# STM32U5G9 register map
File version: 1.3
CPU: CM33 r0p1, little endian, MPU, FPU, 4 interrupt priority bits
Registers are 32-bit, read-write, reset 0x0 unless marked. A register's access mark holds for its fields unless they carry their own. Offsets are from the block's base; [hi:lo] are bit positions; 'fields as' and 'values as' point back to an identical list.

## HSPI1
Base 0x420D3400
Same registers: SEC_HSPI1 0x520D3400
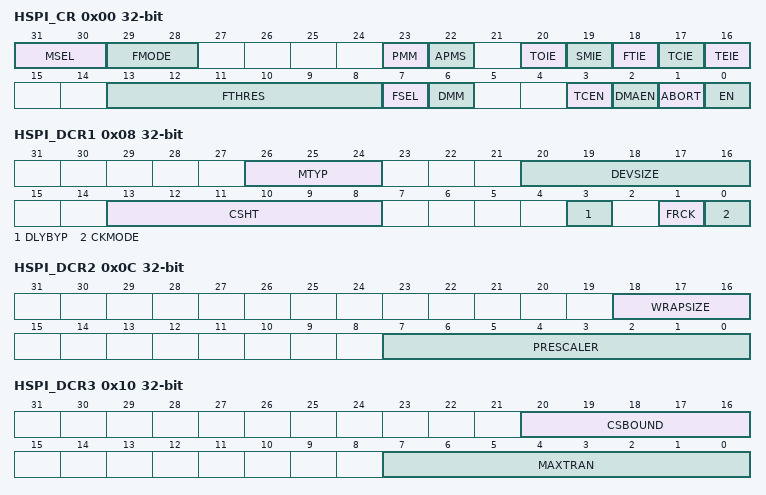
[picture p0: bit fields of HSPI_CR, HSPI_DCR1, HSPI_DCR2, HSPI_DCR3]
0x00 HSPI_CR — HSPI control register
  [31:30] MSEL — Flash select
    0=data exchanged over IO[3:0]; 1=data exchanged over IO[7:4]; 2=data exchanged over IO11:8]; 3=data exchanged over IO[15:12]
  [29:28] FMODE — Functional mode
    0=Indirect-write mode; 1=Indirect-read mode; 2=Automatic-polling mode; 3=Memory-mapped mode
  [23] PMM — Polling match mode
    0=AND-match mode, SMF is set if all the unmasked bits received from the device match the corresponding bits in the match register; 1=OR-match mode, SMF is set if any of the unmasked bits received from the device matches its corresponding bit in the match register
  [22] APMS — Automatic-polling mode stop
    0=Automatic-polling mode is stopped only by abort or by disabling the HSPI; 1=Automatic-polling mode stops as soon as there is a match
  [20] TOIE — Timeout interrupt enable
    0=Interrupt disabled; 1=Interrupt enabled
  [19] SMIE — Status match interrupt enable
    0=Interrupt disabled; 1=Interrupt enabled
  [18] FTIE — FIFO threshold interrupt enable
    0=Interrupt disabled; 1=Interrupt enabled
  [17] TCIE — Transfer complete interrupt enable
    0=Interrupt disabled; 1=Interrupt enabled
  [16] TEIE — Transfer error interrupt enable
    0=Interrupt disabled; 1=Interrupt enabled
  [13:8] FTHRES — FIFO threshold level
    0=FTF is set if there are one or more free bytes available to be written to in the FIFO in Indirect-write mode, or if there are one or more valid bytes can be read from the FIFO in Indirect-read mode; 1=FTF is set if there are two or more free bytes available to be written to in the FIFO in Indirect-write mode, or if there are two or more valid bytes can be read from the FIFO in Indirect-read mode; 63=FTF is set if there are 64 free bytes available to be written to in the FIFO in Indirect-write mode, or if there are 64 valid bytes can be read from the FIFO in Indirect-read mode
  [7] FSEL — Memory select
  [6] DMM — Dual-memory mode
    0=Dual-quad mode disabled; 1=Dual-quad mode enabled
  [3] TCEN — Timeout counter enable
    0=Timeout counter is disabled, and thus the chip-select (nCS) remains active indefinitely after an access in Memory-mapped mode; 1=Timeout counter is enabled, and thus the chip-select is released in the Memory-mapped mode after TIMEOUT[15:0] cycles of external device inactivity
  [2] DMAEN — DMA enable
    0=DMA disabled for Indirect mode; 1=DMA enabled for Indirect mode
  [1] ABORT — Abort request
    0=No abort requested; 1=Abort requested
  [0] EN — Enable
    0=HSPI disabled; 1=HSPI enabled
0x08 HSPI_DCR1 — HSPI device configuration register 1
  [26:24] MTYP — Memory type
    0=Micron mode, D0/D1 ordering in DTR 8-data-bit mode. Regular SPI protocol in Octal-, Quad-, Dual- and Single-SPI modes; 1=Macronix mode, D1/D0 ordering in DTR 8-data-bit mode. Regular SPI protocol in Octal-, Quad-, Dual-, and Single-SPI modes; 2=Standard mode; 3=Macronix RAM mode, D1/D0 ordering in DTR 8-data-bit mode. Regular SPI protocol in Octal-, Quad-, Dual-, and Single-SPI with dedicated address mapping.; 4=HyperBus memory mode, the protocol follows the HyperBus specification. 8-data-bit DTR mode must be selected.; 5=HyperBus register mode, addressing register space. The memory-mapped accesses in this mode must be non-cacheable, or Indirect read/write modes must be used.
  [20:16] DEVSIZE — Device size
  [13:8] CSHT — Chip-select high time
    0=nCS stays high for at least 1 cycle between external device commands; 1=nCS stays high for at least 2 cycles between external device commands
  [3] DLYBYP — Delay block bypass
    0=The internal sampling clock (called feedback clock) or the DQS data strobe external signal is delayed by the delay block (for more details on this block, refer to the dedicated section of the reference manual as it is not part of the HSPI); 1=The delay block is bypassed, so the internal sampling clock or the DQS data strobe external signal is not affected by the delay block. The delay is shorter than when the delay block is not bypassed, even with the delay value set to minimum value in delay block.
  [1] FRCK — Free running clock
    0=CLK is not free running; 1=CLK is free running (always provided)
  [0] CKMODE — Mode 0/Mode 3
    0=CLK must stay low while nCS is high (chip-select released). This is referred to as Mode 0.; 1=CLK must stay high while nCS is high (chip-select released). This is referred to as Mode 3.
0x0C HSPI_DCR2 — HSPI device configuration register 2
  [18:16] WRAPSIZE
    0=Wrapped reads are not supported by the memory; 2=External memory supports wrap size of 16 bytes; 3=External memory supports wrap size of 32 bytes; 4=External memory supports wrap size of 64 bytes; 5=External memory supports wrap size of 128 bytes
  [7:0] PRESCALER — Clock prescaler
    0=FCLK = FKERNEL, kernel clock used directly as HSPICLK (prescaler bypassed). In this case, if the DDR mode is used, it is mandatory to provide to the HSPI a kernel clock that has 50% duty-cycle.; 1=FCLK = FKERNEL/2
0x10 HSPI_DCR3 — HSPI device configuration register 3
  [20:16] CSBOUND — CS boundary
    0=CS boundary disabled
  [7:0] MAXTRAN — Maximum transfer
    0=Maximum communication disabled
0x14 HSPI_DCR4 — HSPI device configuration register 4
  [31:0] REFRESH — Refresh rate
    0=Refresh disabled
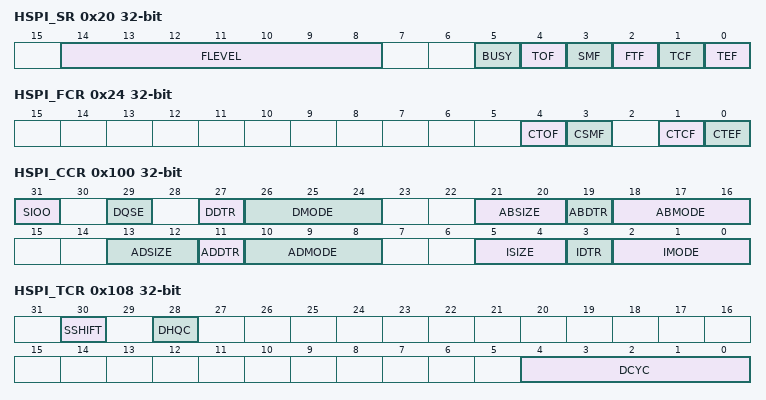
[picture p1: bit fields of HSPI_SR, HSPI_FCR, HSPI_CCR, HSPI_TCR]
0x20 HSPI_SR ro
  [14:8] FLEVEL — FIFO level
  [5] BUSY
  [4] TOF — Timeout flag
  [3] SMF — Status match flag
  [2] FTF — FIFO threshold flag
  [1] TCF — Transfer complete flag
  [0] TEF — Transfer error flag
0x24 HSPI_FCR wo
  [4] CTOF — Clear timeout flag
  [3] CSMF — Clear status match flag
  [1] CTCF — Clear transfer complete flag
  [0] CTEF — Clear transfer error flag
0x40 HSPI_DLR — HSPI data length register
  [31:0] DL — [31: 0]: Data length
0x48 HSPI_AR
  [31:0] ADDRESS
0x50 HSPI_DR
  [31:0] DATA — [31: 0]: Data
0x80 HSPI_PSMKR — HSPI polling status mask register
  [31:0] MASK — Status mask
    0=Bit n of the data received in Automatic-polling mode is masked and its value is not considered in the matching logic; 1=Bit n of the data received in Automatic-polling mode is unmasked and its value is considered in the matching logic
0x88 HSPI_PSMAR — HSPI polling status match register
  [31:0] MATCH — [31: 0]: Status match
0x90 HSPI_PIR — HSPI polling interval register
  [15:0] INTERVAL — [15: 0]: Polling interval
0x100 HSPI_CCR — HSPI communication configuration register
  [31] SIOO — Send instruction only once mode
    0=Send instruction on every transaction; 1=Send instruction only for the first command
  [29] DQSE — DQS enable
    0=DQS disabled; 1=DQS enabled
  [27] DDTR — Data double transfer rate
    0=DTR mode disabled for data phase; 1=DTR mode enabled for data phase
  [26:24] DMODE — Data mode
    0=No data; 1=Data on a single line; 2=Data on two lines; 3=Data on four lines; 4=Data on eight lines; 5=data on 16 lines
  [21:20] ABSIZE — Alternate bytes size
    0=8-bit alternate bytes; 1=16-bit alternate bytes; 2=24-bit alternate bytes; 3=32-bit alternate bytes
  [19] ABDTR — Alternate bytes double transfer rate
    0=DTR mode disabled for alternate bytes phase; 1=DTR mode enabled for alternate bytes phase
  [18:16] ABMODE — Alternate-byte mode
    0=No alternate bytes; 1=Alternate bytes on a single line; 2=Alternate bytes on two lines; 3=Alternate bytes on four lines
  [13:12] ADSIZE — Address size
    0=8-bit address; 1=16-bit address; 2=24-bit address; 3=32-bit address
  [11] ADDTR — Address double transfer rate
    0=DTR mode disabled for address phase; 1=DTR mode enabled for address phase
  [10:8] ADMODE — Address mode
    0=No address; 1=Address on a single line; 2=Address on two lines; 3=Address on four lines; 4=Address on eight lines
  [5:4] ISIZE — Instruction size
    0=8-bit instruction; 1=16-bit instruction; 2=24-bit instruction; 3=32-bit instruction
  [3] IDTR — Instruction double transfer rate
    0=DTR mode disabled for instruction phase; 1=DTR mode enabled for instruction phase
  [2:0] IMODE — Instruction mode
    0=No instruction; 1=Instruction on a single line; 2=Instruction on two lines; 3=Instruction on four lines; 4=Instruction on eight lines
0x108 HSPI_TCR — HSPI timing configuration register
  [30] SSHIFT — Sample shift
    0=No shift; 1=1/2 cycle shift
  [28] DHQC — Delay hold quarter cycle
    0=No delay hold; 1=1/4 cycle hold
  [4:0] DCYC — Number of dummy cycles
0x110 HSPI_IR — HSPI instruction register
  [31:0] INSTRUCTION
0x120 HSPI_ABR — HSPI alternate bytes register
  [31:0] ALTERNATE — [31: 0]: Alternate bytes
0x130 HSPI_LPTR — HSPI low-power timeout register
  [15:0] TIMEOUT — [15: 0]: Timeout period
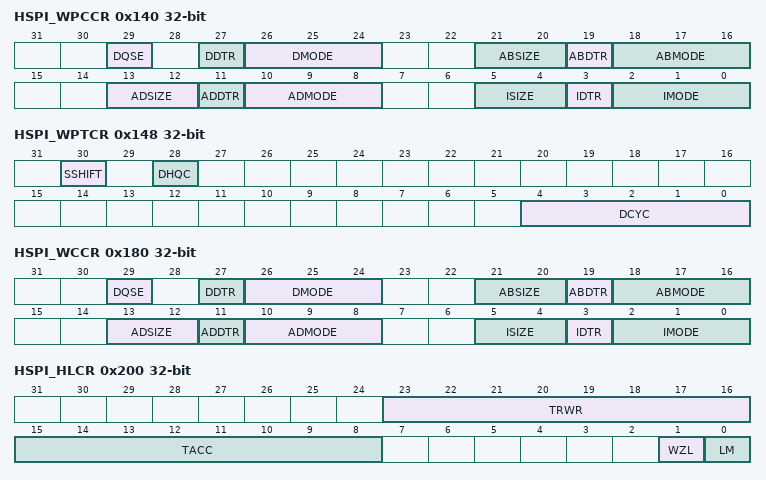
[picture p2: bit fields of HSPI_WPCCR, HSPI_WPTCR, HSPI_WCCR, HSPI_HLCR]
0x140 HSPI_WPCCR — HSPI wrap communication configuration register
  [29] DQSE — DQS enable
    0=DQS disabled; 1=DQS enabled
  [27] DDTR — Data double transfer rate
    values as HSPI_CCR.DDTR
  [26:24] DMODE — Data mode
    0=No data; 1=Data on a single line; 2=Data on two lines; 3=Data on four lines; 4=Data on eight lines
  [21:20] ABSIZE — Alternate bytes size
    values as HSPI_CCR.ABSIZE
  [19] ABDTR — Alternate bytes double transfer rate
    values as HSPI_CCR.ABDTR
  [18:16] ABMODE — Alternate-byte mode
    0=No alternate bytes; 1=Alternate bytes on a single line; 2=Alternate bytes on two lines; 3=Alternate bytes on four lines; 4=Alternate bytes on eight lines; 5=Alternate bytes on 16 lines
  [13:12] ADSIZE — Address size
    values as HSPI_CCR.ADSIZE
  [11] ADDTR — Address double transfer rate
    values as HSPI_CCR.ADDTR
  [10:8] ADMODE — Address mode
    values as HSPI_CCR.ADMODE
  [5:4] ISIZE — Instruction size
    values as HSPI_CCR.ISIZE
  [3] IDTR — Instruction double transfer rate
    values as HSPI_CCR.IDTR
  [2:0] IMODE — Instruction mode
    values as HSPI_CCR.IMODE
0x148 HSPI_WPTCR — HSPI wrap timing configuration register
  [30] SSHIFT — Sample shift
    0=No shift; 1=1/2 cycle shift
  [28] DHQC — Delay hold quarter cycle
    0=No quarter cycle delay; 1=Quarter cycle delay inserted
  [4:0] DCYC — Number of dummy cycles
0x150 HSPI_WPIR — HSPI wrap instruction register
  [31:0] INSTRUCTION — [31: 0]: Instruction
0x160 HSPI_WPABR — HSPI wrap alternate bytes register
  [31:0] ALTERNATE — [31: 0]: Alternate bytes
0x180 HSPI_WCCR — HSPI write communication configuration register
  [29] DQSE — DQS enable
    0=DQS disabled; 1=DQS enabled
  [27] DDTR — data double transfer rate
    values as HSPI_CCR.DDTR
  [26:24] DMODE — Data mode
    0=No data; 1=Data on a single line; 2=Data on two lines; 3=Data on four lines; 4=Data on eight lines; 5=Data on 16 lines
  [21:20] ABSIZE — Alternate bytes size
    values as HSPI_CCR.ABSIZE
  [19] ABDTR — Alternate bytes double-transfer rate
    0=DTR mode disabled for alternate-bytes phase; 1=DTR mode enabled for alternate-bytes phase
  [18:16] ABMODE — Alternate-byte mode
    0=No alternate bytes; 1=Alternate bytes on a single line; 2=Alternate bytes on two lines; 3=Alternate bytes on four lines; 4=Alternate bytes on eight lines
  [13:12] ADSIZE — Address size
    values as HSPI_CCR.ADSIZE
  [11] ADDTR — Address double transfer rate
    values as HSPI_CCR.ADDTR
  [10:8] ADMODE — Address mode
    values as HSPI_CCR.ADMODE
  [5:4] ISIZE — Instruction size
    values as HSPI_CCR.ISIZE
  [3] IDTR — Instruction double transfer rate
    values as HSPI_CCR.IDTR
  [2:0] IMODE — Instruction mode
    values as HSPI_CCR.IMODE
0x188 HSPI_WTCR — HSPI write timing configuration register
  [4:0] DCYC — Number of dummy cycles
0x190 HSPI_WIR — HSPI write instruction register
  [31:0] INSTRUCTION
0x1A0 HSPI_WABR — HSPI write alternate bytes register
  [31:0] ALTERNATE — [31: 0]: Alternate bytes
0x200 HSPI_HLCR — HSPI HyperBus latency configuration register
  [23:16] TRWR — Read write recovery time
  [15:8] TACC — [7: 0]: Access time
  [1] WZL — Write zero latency
    0=Latency on write accesses; 1=No latency on write accesses
  [0] LM — Latency mode
    0=Variable initial latency; 1=Fixed latency
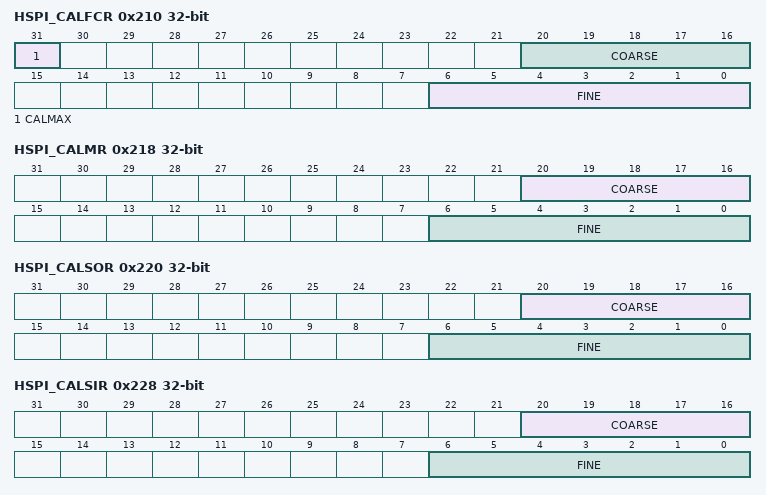
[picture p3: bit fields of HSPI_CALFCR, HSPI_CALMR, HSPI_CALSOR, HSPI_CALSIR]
0x210 HSPI_CALFCR ro — HSPI full-cycle calibration configuration
  [31] CALMAX — Max value
  [20:16] COARSE — [4: 0]: Coarse calibration
  [6:0] FINE — [6: 0]: Fine calibration
0x218 HSPI_CALMR — HSPI DLL master calibration configuration
  [20:16] COARSE — [4: 0]: Coarse calibration
  [6:0] FINE — [6: 0]: Fine calibration
0x220 HSPI_CALSOR — HSPI DLL slave output calibration configuration
  fields as HSPI_CALMR
0x228 HSPI_CALSIR — HSPI DLL slave input calibration configuration
  fields as HSPI_CALMR
